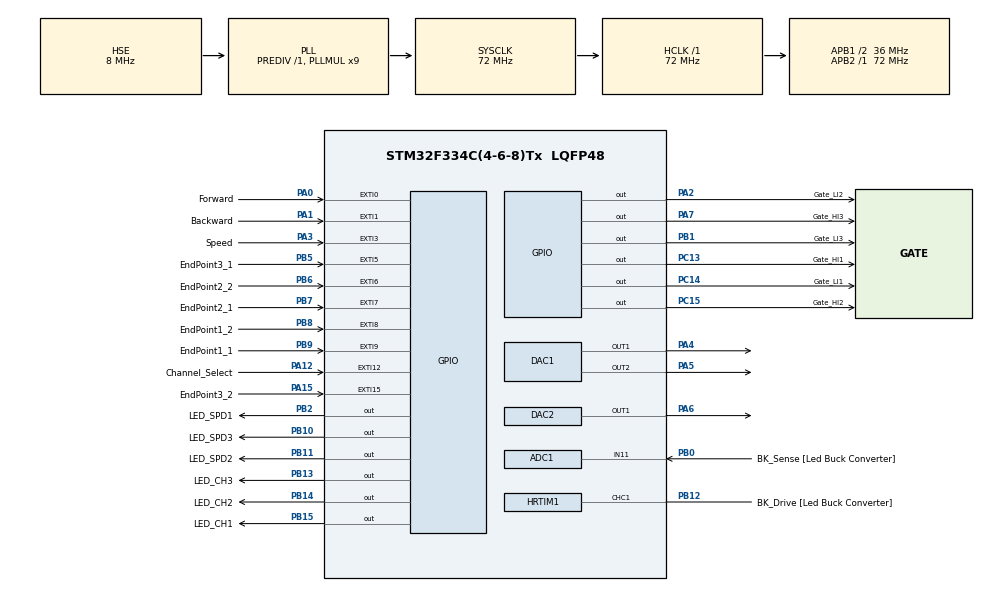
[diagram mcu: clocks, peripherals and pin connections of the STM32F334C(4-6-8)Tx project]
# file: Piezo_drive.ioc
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ADC1.Channel-0\#ChannelRegularConversion=ADC_CHANNEL_11
ADC1.SubFamily=STM32F334x8
ADC1.master=1
DAC1.DAC_Trigger=DAC_TRIGGER_T6_TRGO
DAC1.DAC_Trigger2=DAC_TRIGGER_T6_TRGO
DAC2.DAC_Trigger=DAC_TRIGGER_T6_TRGO
HRTIM1.DMARequests_Semaphore-Output_TC1=ATLEASTONEDMAREQ
HRTIM1.Output1-Output_TC1=HRTIM_OUTPUT_TC1
HRTIM1.TimerIdx-Output_TC1=HRTIM_TIMERINDEX_TIMER_C
Mcu.Family=STM32F3
Mcu.Name=STM32F334C(4-6-8)Tx
Mcu.Package=LQFP48
NVIC.EXTI0_IRQn=true\:0\:0\:true\:false\:true\:true\:true\:true
NVIC.EXTI15_10_IRQn=true\:0\:0\:false\:false\:true\:true\:true\:true
NVIC.EXTI1_IRQn=true\:0\:0\:false\:false\:true\:true\:true\:true
NVIC.EXTI3_IRQn=true\:0\:0\:false\:false\:true\:true\:true\:true
NVIC.EXTI9_5_IRQn=true\:0\:0\:false\:false\:true\:true\:true\:true
NVIC.PriorityGroup=NVIC_PRIORITYGROUP_0
NVIC.TIM6_DAC1_IRQn=true\:0\:0\:false\:false\:true\:true\:true\:true
PA0.GPIO_Label=Forward
PA0.GPIO_ModeDefaultEXTI=GPIO_MODE_IT_RISING_FALLING
PA0.GPIO_PuPd=GPIO_NOPULL
PA0.Signal=GPXTI0
PA1.GPIO_Label=Backward
PA1.GPIO_ModeDefaultEXTI=GPIO_MODE_IT_RISING_FALLING
PA1.Signal=GPXTI1
PA10.GPIO_Label=N2_Drive [Buck/Boost Converter]
PA10.GPIO_ModeDefaultPP=GPIO_MODE_AF_PP
PA10.GPIO_PuPd=GPIO_NOPULL
PA10.GPIO_Speed=GPIO_SPEED_FREQ_LOW
PA10.Signal=HRTIM1_CHB1
PA11.GPIO_Label=P2_Drive [Buck/Boost Converter]
PA11.GPIO_ModeDefaultPP=GPIO_MODE_AF_PP
PA11.GPIO_PuPd=GPIO_NOPULL
PA11.GPIO_Speed=GPIO_SPEED_FREQ_LOW
PA11.Signal=HRTIM1_CHB2
PA12.GPIO_Label=Channel_Select
PA12.Signal=GPXTI12
PA13.GPIO_Label=SWDIO
PA13.Mode=Serial_Wire
PA13.Signal=SYS_JTMS-SWDIO
PA14.GPIO_Label=SWCLK
PA14.Mode=Serial_Wire
PA14.Signal=SYS_JTCK-SWCLK
PA15.GPIO_Label=EndPoint3_2
PA15.Signal=GPXTI15
PA2.GPIO_Label=Gate_LI2
PA2.Signal=GPIO_Output
PA3.GPIO_Label=Speed
PA3.Signal=GPXTI3
PA4.Signal=COMP_DAC11_group
PA5.Signal=COMP_DAC12_group
PA6.Signal=COMP_DAC21_group
PA7.GPIO_Label=Gate_HI3
PA7.Signal=GPIO_Output
PA8.GPIO_Label=P1_Drive [Buck/Boost Converter]
PA8.GPIO_ModeDefaultPP=GPIO_MODE_AF_PP
PA8.GPIO_PuPd=GPIO_NOPULL
PA8.GPIO_Speed=GPIO_SPEED_FREQ_LOW
PA8.Signal=HRTIM1_CHA1
PA9.GPIO_Label=N1_Drive [Buck/Boost Converter]
PA9.GPIO_ModeDefaultPP=GPIO_MODE_AF_PP
PA9.GPIO_PuPd=GPIO_NOPULL
PA9.GPIO_Speed=GPIO_SPEED_FREQ_LOW
PA9.Signal=HRTIM1_CHA2
PB0.GPIO_Label=BK_Sense [Led Buck Converter]
PB0.GPIO_Mode=GPIO_MODE_ANALOG
PB0.GPIO_PuPd=GPIO_NOPULL
PB0.Mode=IN11-Single-Ended
PB0.Signal=ADC1_IN11
PB1.GPIO_Label=Gate_LI3
PB1.Signal=GPIO_Output
PB10.GPIO_Label=LED_SPD3
PB10.Signal=GPIO_Output
PB11.GPIO_Label=LED_SPD2
PB11.Signal=GPIO_Output
PB12.GPIO_Label=BK_Drive [Led Buck Converter]
PB12.GPIO_ModeDefaultPP=GPIO_MODE_AF_PP
PB12.GPIO_PuPd=GPIO_NOPULL
PB12.GPIO_Speed=GPIO_SPEED_FREQ_LOW
PB12.Mode=Output_TC1
PB12.Signal=HRTIM1_CHC1
PB13.GPIO_Label=LED_CH3
PB13.Signal=GPIO_Output
PB14.GPIO_Label=LED_CH2
PB14.Signal=GPIO_Output
PB15.GPIO_Label=LED_CH1
PB15.Signal=GPIO_Output
PB2.GPIO_Label=LED_SPD1
PB2.Signal=GPIO_Output
PB5.GPIO_Label=EndPoint3_1
PB5.Signal=GPXTI5
PB6.GPIO_Label=EndPoint2_2
PB6.Signal=GPXTI6
PB7.GPIO_Label=EndPoint2_1
PB7.Signal=GPXTI7
PB8.GPIO_Label=EndPoint1_2
PB8.Signal=GPXTI8
PB9.GPIO_Label=EndPoint1_1
PB9.Signal=GPXTI9
PC13.GPIO_Label=Gate_HI1
PC13.Signal=GPIO_Output
PC14\ /\ OSC32_IN.GPIO_Label=Gate_LI1
PC14\ /\ OSC32_IN.Signal=GPIO_Output
PC15\ /\ OSC32_OUT.GPIO_Label=Gate_HI2
PC15\ /\ OSC32_OUT.Signal=GPIO_Output
PF0\ /\ OSC_IN.GPIO_Label=PF0-OSC_IN
PF0\ /\ OSC_IN.Mode=HSE-External-Clock-Source
PF0\ /\ OSC_IN.Signal=RCC_OSC_IN
PF1\ /\ OSC_OUT.GPIO_Label=PF1_OSC_OUT
PF1\ /\ OSC_OUT.Signal=RCC_OSC_OUT
ProjectManager.HeapSize=0x200
ProjectManager.StackSize=0x400
ProjectManager.TargetToolchain=STM32CubeIDE
RCC.AHBFreq_Value=72000000
RCC.APB1CLKDivider=RCC_HCLK_DIV2
RCC.APB1Freq_Value=36000000
RCC.APB1TimFreq_Value=72000000
RCC.APB2Freq_Value=72000000
RCC.APB2TimFreq_Value=72000000
RCC.CortexFreq_Value=72000000
RCC.HCLKFreq_Value=72000000
RCC.HSE_VALUE=8000000
RCC.HSI_VALUE=8000000
RCC.LSE_VALUE=32768
RCC.PLLMUL=RCC_PLL_MUL9
RCC.PLLSourceVirtual=RCC_PLLSOURCE_HSE
RCC.SYSCLKFreq_VALUE=72000000
RCC.SYSCLKSourceVirtual=RCC_SYSCLKSOURCE_PLLCLK
SH.COMP_DAC11_group.0=DAC1_OUT1,DAC_OUT1
SH.COMP_DAC12_group.0=DAC1_OUT2,DAC_OUT2
SH.COMP_DAC21_group.0=DAC2_OUT1,Switch_Enable_OUT1
TIM6.Period=16-1
TIM6.Prescaler=32-1
TIM6.TIM_MasterOutputTrigger=TIM_TRGO_UPDATE
VP_TIM6_VS_ClockSourceINT.Mode=Enable_Timer
board=STM32F3348-DISCO

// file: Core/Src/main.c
/* USER CODE BEGIN Header */
/**
  ******************************************************************************
  * @file           : main.c
  * @brief          : Main program body
  ******************************************************************************
  * @attention
  *
  * Copyright (c) 2024 STMicroelectronics.
  * All rights reserved.
  *
  * This software is licensed under terms that can be found in the LICENSE file
  * in the root directory of this software component.
  * If no LICENSE file comes with this software, it is provided AS-IS.
  *
  ******************************************************************************
  */
/* USER CODE END Header */
#include "main.h"

/* USER CODE BEGIN Includes */
#include "stdbool.h"
/* USER CODE END Includes */

/* USER CODE BEGIN PD */
#define Pi 3.1415926
#define lutLen 2048			//Length of the full period
/* USER CODE END PD */

ADC_HandleTypeDef hadc1;

DAC_HandleTypeDef hdac1;
DAC_HandleTypeDef hdac2;

HRTIM_HandleTypeDef hhrtim1;

TIM_HandleTypeDef htim6;

/* USER CODE BEGIN PV */
uint8_t spd = 30;
uint8_t channel = 1;
bool gateOn = false;
bool buttonPress = false;
bool buttonRelease = false;
bool backwards = false;
bool pulse = false;
bool endPoint = false;
bool bootCharging = false;
uint16_t phaseAccumulator = 0;
uint8_t phaseIncrement;
uint8_t pulseLen;
uint16_t pulseAccumulator = 0;
float amplitude;
float offset;
uint16_t phaseShift;
const uint16_t *Lut;
uint16_t periodLen;
uint32_t stepNumber;
uint32_t stepCounter = 0;

//Two full sine periods
const uint16_t sinLut[2*lutLen] = {
32767,32868,32968,33069,33169,33270,33370,33471,
33571,33672,33772,33873,33973,34074,34174,34274,
34375,34475,34576,34676,34776,34877,34977,35077,
35177,35278,35378,35478,35578,35678,35779,35879,
35979,36079,36179,36279,36379,36479,36578,36678,
36778,36878,36977,37077,37177,37276,37376,37475,
37575,37674,37774,37873,37972,38072,38171,38270,
38369,38468,38567,38666,38765,38863,38962,39061,
39160,39258,39357,39455,39553,39652,39750,39848,
39946,40044,40142,40240,40338,40436,40534,40631,
40729,40826,40924,41021,41118,41215,41312,41409,
41506,41603,41700,41797,41893,41990,42086,42183,
42279,42375,42471,42567,42663,42759,42854,42950,
43045,43141,43236,43331,43426,43521,43616,43711,
43806,43900,43995,44089,44184,44278,44372,44466,
44560,44653,44747,44841,44934,45027,45120,45213,
45306,45399,45492,45584,45677,45769,45861,45954,
46046,46137,46229,46321,46412,46503,46595,46686,
46777,46868,46958,47049,47139,47229,47320,47410,
47499,47589,47679,47768,47857,47947,48036,48125,
48213,48302,48390,48479,48567,48655,48743,48830,
48918,49005,49092,49180,49266,49353,49440,49526,
49613,49699,49785,49871,49956,50042,50127,50212,
50297,50382,50467,50551,50636,50720,50804,50888,
50971,51055,51138,51221,51304,51387,51470,51552,
51635,51717,51799,51880,51962,52043,52124,52205,
52286,52367,52447,52528,52608,52688,52767,52847,
52926,53005,53084,53163,53242,53320,53398,53476,
53554,53632,53709,53786,53863,53940,54017,54093,
54170,54246,54321,54397,54472,54548,54623,54697,
54772,54846,54921,54994,55068,55142,55215,55288,
55361,55434,55506,55579,55651,55723,55794,55866,
55937,56008,56078,56149,56219,56289,56359,56429,
56498,56568,56637,56705,56774,56842,56910,56978,
57046,57113,57180,57247,57314,57380,57447,57513,
57578,57644,57709,57774,57839,57904,57968,58032,
58096,58160,58223,58286,58349,58412,58475,58537,
58599,58660,58722,58783,58844,58905,58965,59026,
59086,59145,59205,59264,59323,59382,59441,59499,
59557,59615,59672,59729,59786,59843,59900,59956,
60012,60067,60123,60178,60233,60288,60342,60396,
60450,60504,60557,60610,60663,60716,60768,60820,
60872,60924,60975,61026,61077,61127,61178,61227,
61277,61327,61376,61425,61473,61522,61570,61617,
61665,61712,61759,61806,61852,61898,61944,61990,
62035,62080,62125,62170,62214,62258,62301,62345,
62388,62431,62473,62516,62558,62599,62641,62682,
62723,62764,62804,62844,62884,62923,62962,63001,
63040,63078,63116,63154,63191,63229,63265,63302,
63338,63374,63410,63446,63481,63516,63550,63585,
63619,63652,63686,63719,63752,63784,63817,63849,
63880,63912,63943,63973,64004,64034,64064,64094,
64123,64152,64181,64209,64237,64265,64293,64320,
64347,64374,64400,64426,64452,64477,64503,64527,
64552,64576,64600,64624,64647,64670,64693,64716,
64738,64760,64781,64803,64824,64844,64865,64885,
64904,64924,64943,64962,64980,64999,65017,65034,
65052,65069,65085,65102,65118,65134,65149,65164,
65179,65194,65208,65222,65236,65249,65262,65275,
65288,65300,65312,65323,65334,65345,65356,65366,
65376,65386,65395,65404,65413,65422,65430,65438,
65445,65452,65459,65466,65472,65478,65484,65489,
65495,65499,65504,65508,65512,65515,65519,65522,
65524,65526,65528,65530,65532,65533,65533,65534,
65534,65534,65533,65533,65532,65530,65528,65526,
65524,65522,65519,65515,65512,65508,65504,65499,
65495,65489,65484,65478,65472,65466,65459,65452,
65445,65438,65430,65422,65413,65404,65395,65386,
65376,65366,65356,65345,65334,65323,65312,65300,
65288,65275,65262,65249,65236,65222,65208,65194,
65179,65164,65149,65134,65118,65102,65085,65069,
65052,65034,65017,64999,64980,64962,64943,64924,
64904,64885,64865,64844,64824,64803,64781,64760,
64738,64716,64693,64670,64647,64624,64600,64576,
64552,64527,64503,64477,64452,64426,64400,64374,
64347,64320,64293,64265,64237,64209,64181,64152,
64123,64094,64064,64034,64004,63973,63943,63912,
63880,63849,63817,63784,63752,63719,63686,63652,
63619,63585,63550,63516,63481,63446,63410,63374,
63338,63302,63265,63229,63191,63154,63116,63078,
63040,63001,62962,62923,62884,62844,62804,62764,
62723,62682,62641,62599,62558,62516,62473,62431,
62388,62345,62301,62258,62214,62170,62125,62080,
62035,61990,61944,61898,61852,61806,61759,61712,
61665,61617,61570,61522,61473,61425,61376,61327,
61277,61227,61178,61127,61077,61026,60975,60924,
60872,60820,60768,60716,60663,60610,60557,60504,
60450,60396,60342,60288,60233,60178,60123,60067,
60012,59956,59900,59843,59786,59729,59672,59615,
59557,59499,59441,59382,59323,59264,59205,59145,
59086,59026,58965,58905,58844,58783,58722,58660,
58599,58537,58475,58412,58349,58286,58223,58160,
58096,58032,57968,57904,57839,57774,57709,57644,
57578,57513,57447,57380,57314,57247,57180,57113,
57046,56978,56910,56842,56774,56705,56637,56568,
56498,56429,56359,56289,56219,56149,56078,56008,
55937,55866,55794,55723,55651,55579,55506,55434,
55361,55288,55215,55142,55068,54994,54921,54846,
54772,54697,54623,54548,54472,54397,54321,54246,
54170,54093,54017,53940,53863,53786,53709,53632,
53554,53476,53398,53320,53242,53163,53084,53005,
52926,52847,52767,52688,52608,52528,52447,52367,
52286,52205,52124,52043,51962,51880,51799,51717,
51635,51552,51470,51387,51304,51221,51138,51055,
50971,50888,50804,50720,50636,50551,50467,50382,
50297,50212,50127,50042,49956,49871,49785,49699,
49613,49526,49440,49353,49266,49180,49092,49005,
48918,48830,48743,48655,48567,48479,48390,48302,
48213,48125,48036,47947,47857,47768,47679,47589,
47499,47410,47320,47229,47139,47049,46958,46868,
46777,46686,46595,46503,46412,46321,46229,46137,
46046,45954,45861,45769,45677,45584,45492,45399,
45306,45213,45120,45027,44934,44841,44747,44653,
44560,44466,44372,44278,44184,44089,43995,43900,
43806,43711,43616,43521,43426,43331,43236,43141,
43045,42950,42854,42759,42663,42567,42471,42375,
42279,42183,42086,41990,41893,41797,41700,41603,
41506,41409,41312,41215,41118,41021,40924,40826,
40729,40631,40534,40436,40338,40240,40142,40044,
39946,39848,39750,39652,39553,39455,39357,39258,
39160,39061,38962,38863,38765,38666,38567,38468,
38369,38270,38171,38072,37972,37873,37774,37674,
37575,37475,37376,37276,37177,37077,36977,36878,
36778,36678,36578,36479,36379,36279,36179,36079,
35979,35879,35779,35678,35578,35478,35378,35278,
35177,35077,34977,34877,34776,34676,34576,34475,
34375,34274,34174,34074,33973,33873,33772,33672,
33571,33471,33370,33270,33169,33069,32968,32868,
32767,32666,32566,32465,32365,32264,32164,32063,
31963,31862,31762,31661,31561,31460,31360,31260,
31159,31059,30958,30858,30758,30657,30557,30457,
30357,30256,30156,30056,29956,29856,29755,29655,
29555,29455,29355,29255,29155,29055,28956,28856,
28756,28656,28557,28457,28357,28258,28158,28059,
27959,27860,27760,27661,27562,27462,27363,27264,
27165,27066,26967,26868,26769,26671,26572,26473,
26374,26276,26177,26079,25981,25882,25784,25686,
25588,25490,25392,25294,25196,25098,25000,24903,
24805,24708,24610,24513,24416,24319,24222,24125,
24028,23931,23834,23737,23641,23544,23448,23351,
23255,23159,23063,22967,22871,22775,22680,22584,
22489,22393,22298,22203,22108,22013,21918,21823,
21728,21634,21539,21445,21350,21256,21162,21068,
20974,20881,20787,20693,20600,20507,20414,20321,
20228,20135,20042,19950,19857,19765,19673,19580,
19488,19397,19305,19213,19122,19031,18939,18848,
18757,18666,18576,18485,18395,18305,18214,18124,
18035,17945,17855,17766,17677,17587,17498,17409,
17321,17232,17144,17055,16967,16879,16791,16704,
16616,16529,16442,16354,16268,16181,16094,16008,
15921,15835,15749,15663,15578,15492,15407,15322,
15237,15152,15067,14983,14898,14814,14730,14646,
14563,14479,14396,14313,14230,14147,14064,13982,
13899,13817,13735,13654,13572,13491,13410,13329,
13248,13167,13087,13006,12926,12846,12767,12687,
12608,12529,12450,12371,12292,12214,12136,12058,
11980,11902,11825,11748,11671,11594,11517,11441,
11364,11288,11213,11137,11062,10986,10911,10837,
10762,10688,10613,10540,10466,10392,10319,10246,
10173,10100,10028, 9955, 9883, 9811, 9740, 9668,
 9597, 9526, 9456, 9385, 9315, 9245, 9175, 9105,
 9036, 8966, 8897, 8829, 8760, 8692, 8624, 8556,
 8488, 8421, 8354, 8287, 8220, 8154, 8087, 8021,
 7956, 7890, 7825, 7760, 7695, 7630, 7566, 7502,
 7438, 7374, 7311, 7248, 7185, 7122, 7059, 6997,
 6935, 6874, 6812, 6751, 6690, 6629, 6569, 6508,
 6448, 6389, 6329, 6270, 6211, 6152, 6093, 6035,
 5977, 5919, 5862, 5805, 5748, 5691, 5634, 5578,
 5522, 5467, 5411, 5356, 5301, 5246, 5192, 5138,
 5084, 5030, 4977, 4924, 4871, 4818, 4766, 4714,
 4662, 4610, 4559, 4508, 4457, 4407, 4356, 4307,
 4257, 4207, 4158, 4109, 4061, 4012, 3964, 3917,
 3869, 3822, 3775, 3728, 3682, 3636, 3590, 3544,
 3499, 3454, 3409, 3364, 3320, 3276, 3233, 3189,
 3146, 3103, 3061, 3018, 2976, 2935, 2893, 2852,
 2811, 2770, 2730, 2690, 2650, 2611, 2572, 2533,
 2494, 2456, 2418, 2380, 2343, 2305, 2269, 2232,
 2196, 2160, 2124, 2088, 2053, 2018, 1984, 1949,
 1915, 1882, 1848, 1815, 1782, 1750, 1717, 1685,
 1654, 1622, 1591, 1561, 1530, 1500, 1470, 1440,
 1411, 1382, 1353, 1325, 1297, 1269, 1241, 1214,
 1187, 1160, 1134, 1108, 1082, 1057, 1031, 1007,
  982,  958,  934,  910,  887,  864,  841,  818,
  796,  774,  753,  731,  710,  690,  669,  649,
  630,  610,  591,  572,  554,  535,  517,  500,
  482,  465,  449,  432,  416,  400,  385,  370,
  355,  340,  326,  312,  298,  285,  272,  259,
  246,  234,  222,  211,  200,  189,  178,  168,
  158,  148,  139,  130,  121,  112,  104,   96,
   89,   82,   75,   68,   62,   56,   50,   45,
   39,   35,   30,   26,   22,   19,   15,   12,
   10,    8,    6,    4,    2,    1,    1,    0,
    0,    0,    1,    1,    2,    4,    6,    8,
   10,   12,   15,   19,   22,   26,   30,   35,
   39,   45,   50,   56,   62,   68,   75,   82,
   89,   96,  104,  112,  121,  130,  139,  148,
  158,  168,  178,  189,  200,  211,  222,  234,
  246,  259,  272,  285,  298,  312,  326,  340,
  355,  370,  385,  400,  416,  432,  449,  465,
  482,  500,  517,  535,  554,  572,  591,  610,
  630,  649,  669,  690,  710,  731,  753,  774,
  796,  818,  841,  864,  887,  910,  934,  958,
  982, 1007, 1031, 1057, 1082, 1108, 1134, 1160,
 1187, 1214, 1241, 1269, 1297, 1325, 1353, 1382,
 1411, 1440, 1470, 1500, 1530, 1561, 1591, 1622,
 1654, 1685, 1717, 1750, 1782, 1815, 1848, 1882,
 1915, 1949, 1984, 2018, 2053, 2088, 2124, 2160,
 2196, 2232, 2269, 2305, 2343, 2380, 2418, 2456,
 2494, 2533, 2572, 2611, 2650, 2690, 2730, 2770,
 2811, 2852, 2893, 2935, 2976, 3018, 3061, 3103,
 3146, 3189, 3233, 3276, 3320, 3364, 3409, 3454,
 3499, 3544, 3590, 3636, 3682, 3728, 3775, 3822,
 3869, 3917, 3964, 4012, 4061, 4109, 4158, 4207,
 4257, 4307, 4356, 4407, 4457, 4508, 4559, 4610,
 4662, 4714, 4766, 4818, 4871, 4924, 4977, 5030,
 5084, 5138, 5192, 5246, 5301, 5356, 5411, 5467,
 5522, 5578, 5634, 5691, 5748, 5805, 5862, 5919,
 5977, 6035, 6093, 6152, 6211, 6270, 6329, 6389,
 6448, 6508, 6569, 6629, 6690, 6751, 6812, 6874,
 6935, 6997, 7059, 7122, 7185, 7248, 7311, 7374,
 7438, 7502, 7566, 7630, 7695, 7760, 7825, 7890,
 7956, 8021, 8087, 8154, 8220, 8287, 8354, 8421,
 8488, 8556, 8624, 8692, 8760, 8829, 8897, 8966,
 9036, 9105, 9175, 9245, 9315, 9385, 9456, 9526,
 9597, 9668, 9740, 9811, 9883, 9955,10028,10100,
10173,10246,10319,10392,10466,10540,10613,10688,
10762,10837,10911,10986,11062,11137,11213,11288,
11364,11441,11517,11594,11671,11748,11825,11902,
11980,12058,12136,12214,12292,12371,12450,12529,
12608,12687,12767,12846,12926,13006,13087,13167,
13248,13329,13410,13491,13572,13654,13735,13817,
13899,13982,14064,14147,14230,14313,14396,14479,
14563,14646,14730,14814,14898,14983,15067,15152,
15237,15322,15407,15492,15578,15663,15749,15835,
15921,16008,16094,16181,16268,16354,16442,16529,
16616,16704,16791,16879,16967,17055,17144,17232,
17321,17409,17498,17587,17677,17766,17855,17945,
18035,18124,18214,18305,18395,18485,18576,18666,
18757,18848,18939,19031,19122,19213,19305,19397,
19488,19580,19673,19765,19857,19950,20042,20135,
20228,20321,20414,20507,20600,20693,20787,20881,
20974,21068,21162,21256,21350,21445,21539,21634,
21728,21823,21918,22013,22108,22203,22298,22393,
22489,22584,22680,22775,22871,22967,23063,23159,
23255,23351,23448,23544,23641,23737,23834,23931,
24028,24125,24222,24319,24416,24513,24610,24708,
24805,24903,25000,25098,25196,25294,25392,25490,
25588,25686,25784,25882,25981,26079,26177,26276,
26374,26473,26572,26671,26769,26868,26967,27066,
27165,27264,27363,27462,27562,27661,27760,27860,
27959,28059,28158,28258,28357,28457,28557,28656,
28756,28856,28956,29055,29155,29255,29355,29455,
29555,29655,29755,29856,29956,30056,30156,30256,
30357,30457,30557,30657,30758,30858,30958,31059,
31159,31260,31360,31460,31561,31661,31762,31862,
31963,32063,32164,32264,32365,32465,32566,32666,
32767,32868,32968,33069,33169,33270,33370,33471,
33571,33672,33772,33873,33973,34074,34174,34274,
34375,34475,34576,34676,34776,34877,34977,35077,
35177,35278,35378,35478,35578,35678,35779,35879,
35979,36079,36179,36279,36379,36479,36578,36678,
36778,36878,36977,37077,37177,37276,37376,37475,
37575,37674,37774,37873,37972,38072,38171,38270,
38369,38468,38567,38666,38765,38863,38962,39061,
39160,39258,39357,39455,39553,39652,39750,39848,
39946,40044,40142,40240,40338,40436,40534,40631,
40729,40826,40924,41021,41118,41215,41312,41409,
41506,41603,41700,41797,41893,41990,42086,42183,
42279,42375,42471,42567,42663,42759,42854,42950,
43045,43141,43236,43331,43426,43521,43616,43711,
43806,43900,43995,44089,44184,44278,44372,44466,
44560,44653,44747,44841,44934,45027,45120,45213,
45306,45399,45492,45584,45677,45769,45861,45954,
46046,46137,46229,46321,46412,46503,46595,46686,
46777,46868,46958,47049,47139,47229,47320,47410,
47499,47589,47679,47768,47857,47947,48036,48125,
48213,48302,48390,48479,48567,48655,48743,48830,
48918,49005,49092,49180,49266,49353,49440,49526,
49613,49699,49785,49871,49956,50042,50127,50212,
50297,50382,50467,50551,50636,50720,50804,50888,
50971,51055,51138,51221,51304,51387,51470,51552,
51635,51717,51799,51880,51962,52043,52124,52205,
52286,52367,52447,52528,52608,52688,52767,52847,
52926,53005,53084,53163,53242,53320,53398,53476,
53554,53632,53709,53786,53863,53940,54017,54093,
54170,54246,54321,54397,54472,54548,54623,54697,
54772,54846,54921,54994,55068,55142,55215,55288,
55361,55434,55506,55579,55651,55723,55794,55866,
55937,56008,56078,56149,56219,56289,56359,56429,
56498,56568,56637,56705,56774,56842,56910,56978,
57046,57113,57180,57247,57314,57380,57447,57513,
57578,57644,57709,57774,57839,57904,57968,58032,
58096,58160,58223,58286,58349,58412,58475,58537,
58599,58660,58722,58783,58844,58905,58965,59026,
59086,59145,59205,59264,59323,59382,59441,59499,
59557,59615,59672,59729,59786,59843,59900,59956,
60012,60067,60123,60178,60233,60288,60342,60396,
60450,60504,60557,60610,60663,60716,60768,60820,
60872,60924,60975,61026,61077,61127,61178,61227,
61277,61327,61376,61425,61473,61522,61570,61617,
61665,61712,61759,61806,61852,61898,61944,61990,
62035,62080,62125,62170,62214,62258,62301,62345,
62388,62431,62473,62516,62558,62599,62641,62682,
62723,62764,62804,62844,62884,62923,62962,63001,
63040,63078,63116,63154,63191,63229,63265,63302,
63338,63374,63410,63446,63481,63516,63550,63585,
63619,63652,63686,63719,63752,63784,63817,63849,
63880,63912,63943,63973,64004,64034,64064,64094,
64123,64152,64181,64209,64237,64265,64293,64320,
64347,64374,64400,64426,64452,64477,64503,64527,
64552,64576,64600,64624,64647,64670,64693,64716,
64738,64760,64781,64803,64824,64844,64865,64885,
64904,64924,64943,64962,64980,64999,65017,65034,
65052,65069,65085,65102,65118,65134,65149,65164,
65179,65194,65208,65222,65236,65249,65262,65275,
65288,65300,65312,65323,65334,65345,65356,65366,
65376,65386,65395,65404,65413,65422,65430,65438,
65445,65452,65459,65466,65472,65478,65484,65489,
65495,65499,65504,65508,65512,65515,65519,65522,
65524,65526,65528,65530,65532,65533,65533,65534,
65534,65534,65533,65533,65532,65530,65528,65526,
65524,65522,65519,65515,65512,65508,65504,65499,
65495,65489,65484,65478,65472,65466,65459,65452,
65445,65438,65430,65422,65413,65404,65395,65386,
65376,65366,65356,65345,65334,65323,65312,65300,
65288,65275,65262,65249,65236,65222,65208,65194,
65179,65164,65149,65134,65118,65102,65085,65069,
65052,65034,65017,64999,64980,64962,64943,64924,
64904,64885,64865,64844,64824,64803,64781,64760,
64738,64716,64693,64670,64647,64624,64600,64576,
64552,64527,64503,64477,64452,64426,64400,64374,
64347,64320,64293,64265,64237,64209,64181,64152,
64123,64094,64064,64034,64004,63973,63943,63912,
63880,63849,63817,63784,63752,63719,63686,63652,
63619,63585,63550,63516,63481,63446,63410,63374,
63338,63302,63265,63229,63191,63154,63116,63078,
63040,63001,62962,62923,62884,62844,62804,62764,
62723,62682,62641,62599,62558,62516,62473,62431,
62388,62345,62301,62258,62214,62170,62125,62080,
62035,61990,61944,61898,61852,61806,61759,61712,
61665,61617,61570,61522,61473,61425,61376,61327,
61277,61227,61178,61127,61077,61026,60975,60924,
60872,60820,60768,60716,60663,60610,60557,60504,
60450,60396,60342,60288,60233,60178,60123,60067,
60012,59956,59900,59843,59786,59729,59672,59615,
59557,59499,59441,59382,59323,59264,59205,59145,
59086,59026,58965,58905,58844,58783,58722,58660,
58599,58537,58475,58412,58349,58286,58223,58160,
58096,58032,57968,57904,57839,57774,57709,57644,
57578,57513,57447,57380,57314,57247,57180,57113,
57046,56978,56910,56842,56774,56705,56637,56568,
56498,56429,56359,56289,56219,56149,56078,56008,
55937,55866,55794,55723,55651,55579,55506,55434,
55361,55288,55215,55142,55068,54994,54921,54846,
54772,54697,54623,54548,54472,54397,54321,54246,
54170,54093,54017,53940,53863,53786,53709,53632,
53554,53476,53398,53320,53242,53163,53084,53005,
52926,52847,52767,52688,52608,52528,52447,52367,
52286,52205,52124,52043,51962,51880,51799,51717,
51635,51552,51470,51387,51304,51221,51138,51055,
50971,50888,50804,50720,50636,50551,50467,50382,
50297,50212,50127,50042,49956,49871,49785,49699,
49613,49526,49440,49353,49266,49180,49092,49005,
48918,48830,48743,48655,48567,48479,48390,48302,
48213,48125,48036,47947,47857,47768,47679,47589,
47499,47410,47320,47229,47139,47049,46958,46868,
46777,46686,46595,46503,46412,46321,46229,46137,
46046,45954,45861,45769,45677,45584,45492,45399,
45306,45213,45120,45027,44934,44841,44747,44653,
44560,44466,44372,44278,44184,44089,43995,43900,
43806,43711,43616,43521,43426,43331,43236,43141,
43045,42950,42854,42759,42663,42567,42471,42375,
42279,42183,42086,41990,41893,41797,41700,41603,
41506,41409,41312,41215,41118,41021,40924,40826,
40729,40631,40534,40436,40338,40240,40142,40044,
39946,39848,39750,39652,39553,39455,39357,39258,
39160,39061,38962,38863,38765,38666,38567,38468,
38369,38270,38171,38072,37972,37873,37774,37674,
37575,37475,37376,37276,37177,37077,36977,36878,
36778,36678,36578,36479,36379,36279,36179,36079,
35979,35879,35779,35678,35578,35478,35378,35278,
35177,35077,34977,34877,34776,34676,34576,34475,
34375,34274,34174,34074,33973,33873,33772,33672,
33571,33471,33370,33270,33169,33069,32968,32868,
32767,32666,32566,32465,32365,32264,32164,32063,
31963,31862,31762,31661,31561,31460,31360,31260,
31159,31059,30958,30858,30758,30657,30557,30457,
30357,30256,30156,30056,29956,29856,29755,29655,
29555,29455,29355,29255,29155,29055,28956,28856,
28756,28656,28557,28457,28357,28258,28158,28059,
27959,27860,27760,27661,27562,27462,27363,27264,
27165,27066,26967,26868,26769,26671,26572,26473,
26374,26276,26177,26079,25981,25882,25784,25686,
25588,25490,25392,25294,25196,25098,25000,24903,
24805,24708,24610,24513,24416,24319,24222,24125,
24028,23931,23834,23737,23641,23544,23448,23351,
23255,23159,23063,22967,22871,22775,22680,22584,
22489,22393,22298,22203,22108,22013,21918,21823,
21728,21634,21539,21445,21350,21256,21162,21068,
20974,20881,20787,20693,20600,20507,20414,20321,
20228,20135,20042,19950,19857,19765,19673,19580,
19488,19397,19305,19213,19122,19031,18939,18848,
18757,18666,18576,18485,18395,18305,18214,18124,
18035,17945,17855,17766,17677,17587,17498,17409,
17321,17232,17144,17055,16967,16879,16791,16704,
16616,16529,16442,16354,16268,16181,16094,16008,
15921,15835,15749,15663,15578,15492,15407,15322,
15237,15152,15067,14983,14898,14814,14730,14646,
14563,14479,14396,14313,14230,14147,14064,13982,
13899,13817,13735,13654,13572,13491,13410,13329,
13248,13167,13087,13006,12926,12846,12767,12687,
12608,12529,12450,12371,12292,12214,12136,12058,
11980,11902,11825,11748,11671,11594,11517,11441,
11364,11288,11213,11137,11062,10986,10911,10837,
10762,10688,10613,10540,10466,10392,10319,10246,
10173,10100,10028, 9955, 9883, 9811, 9740, 9668,
 9597, 9526, 9456, 9385, 9315, 9245, 9175, 9105,
 9036, 8966, 8897, 8829, 8760, 8692, 8624, 8556,
 8488, 8421, 8354, 8287, 8220, 8154, 8087, 8021,
 7956, 7890, 7825, 7760, 7695, 7630, 7566, 7502,
 7438, 7374, 7311, 7248, 7185, 7122, 7059, 6997,
 6935, 6874, 6812, 6751, 6690, 6629, 6569, 6508,
 6448, 6389, 6329, 6270, 6211, 6152, 6093, 6035,
 5977, 5919, 5862, 5805, 5748, 5691, 5634, 5578,
 5522, 5467, 5411, 5356, 5301, 5246, 5192, 5138,
 5084, 5030, 4977, 4924, 4871, 4818, 4766, 4714,
 4662, 4610, 4559, 4508, 4457, 4407, 4356, 4307,
 4257, 4207, 4158, 4109, 4061, 4012, 3964, 3917,
 3869, 3822, 3775, 3728, 3682, 3636, 3590, 3544,
 3499, 3454, 3409, 3364, 3320, 3276, 3233, 3189,
 3146, 3103, 3061, 3018, 2976, 2935, 2893, 2852,
 2811, 2770, 2730, 2690, 2650, 2611, 2572, 2533,
 2494, 2456, 2418, 2380, 2343, 2305, 2269, 2232,
 2196, 2160, 2124, 2088, 2053, 2018, 1984, 1949,
 1915, 1882, 1848, 1815, 1782, 1750, 1717, 1685,
 1654, 1622, 1591, 1561, 1530, 1500, 1470, 1440,
 1411, 1382, 1353, 1325, 1297, 1269, 1241, 1214,
 1187, 1160, 1134, 1108, 1082, 1057, 1031, 1007,
  982,  958,  934,  910,  887,  864,  841,  818,
  796,  774,  753,  731,  710,  690,  669,  649,
  630,  610,  591,  572,  554,  535,  517,  500,
  482,  465,  449,  432,  416,  400,  385,  370,
  355,  340,  326,  312,  298,  285,  272,  259,
  246,  234,  222,  211,  200,  189,  178,  168,
  158,  148,  139,  130,  121,  112,  104,   96,
   89,   82,   75,   68,   62,   56,   50,   45,
   39,   35,   30,   26,   22,   19,   15,   12,
   10,    8,    6,    4,    2,    1,    1,    0,
    0,    0,    1,    1,    2,    4,    6,    8,
   10,   12,   15,   19,   22,   26,   30,   35,
   39,   45,   50,   56,   62,   68,   75,   82,
   89,   96,  104,  112,  121,  130,  139,  148,
  158,  168,  178,  189,  200,  211,  222,  234,
  246,  259,  272,  285,  298,  312,  326,  340,
  355,  370,  385,  400,  416,  432,  449,  465,
  482,  500,  517,  535,  554,  572,  591,  610,
  630,  649,  669,  690,  710,  731,  753,  774,
  796,  818,  841,  864,  887,  910,  934,  958,
  982, 1007, 1031, 1057, 1082, 1108, 1134, 1160,
 1187, 1214, 1241, 1269, 1297, 1325, 1353, 1382,
 1411, 1440, 1470, 1500, 1530, 1561, 1591, 1622,
 1654, 1685, 1717, 1750, 1782, 1815, 1848, 1882,
 1915, 1949, 1984, 2018, 2053, 2088, 2124, 2160,
 2196, 2232, 2269, 2305, 2343, 2380, 2418, 2456,
 2494, 2533, 2572, 2611, 2650, 2690, 2730, 2770,
 2811, 2852, 2893, 2935, 2976, 3018, 3061, 3103,
 3146, 3189, 3233, 3276, 3320, 3364, 3409, 3454,
 3499, 3544, 3590, 3636, 3682, 3728, 3775, 3822,
 3869, 3917, 3964, 4012, 4061, 4109, 4158, 4207,
 4257, 4307, 4356, 4407, 4457, 4508, 4559, 4610,
 4662, 4714, 4766, 4818, 4871, 4924, 4977, 5030,
 5084, 5138, 5192, 5246, 5301, 5356, 5411, 5467,
 5522, 5578, 5634, 5691, 5748, 5805, 5862, 5919,
 5977, 6035, 6093, 6152, 6211, 6270, 6329, 6389,
 6448, 6508, 6569, 6629, 6690, 6751, 6812, 6874,
 6935, 6997, 7059, 7122, 7185, 7248, 7311, 7374,
 7438, 7502, 7566, 7630, 7695, 7760, 7825, 7890,
 7956, 8021, 8087, 8154, 8220, 8287, 8354, 8421,
 8488, 8556, 8624, 8692, 8760, 8829, 8897, 8966,
 9036, 9105, 9175, 9245, 9315, 9385, 9456, 9526,
 9597, 9668, 9740, 9811, 9883, 9955,10028,10100,
10173,10246,10319,10392,10466,10540,10613,10688,
10762,10837,10911,10986,11062,11137,11213,11288,
11364,11441,11517,11594,11671,11748,11825,11902,
11980,12058,12136,12214,12292,12371,12450,12529,
12608,12687,12767,12846,12926,13006,13087,13167,
13248,13329,13410,13491,13572,13654,13735,13817,
13899,13982,14064,14147,14230,14313,14396,14479,
14563,14646,14730,14814,14898,14983,15067,15152,
15237,15322,15407,15492,15578,15663,15749,15835,
15921,16008,16094,16181,16268,16354,16442,16529,
16616,16704,16791,16879,16967,17055,17144,17232,
17321,17409,17498,17587,17677,17766,17855,17945,
18035,18124,18214,18305,18395,18485,18576,18666,
18757,18848,18939,19031,19122,19213,19305,19397,
19488,19580,19673,19765,19857,19950,20042,20135,
20228,20321,20414,20507,20600,20693,20787,20881,
20974,21068,21162,21256,21350,21445,21539,21634,
21728,21823,21918,22013,22108,22203,22298,22393,
22489,22584,22680,22775,22871,22967,23063,23159,
23255,23351,23448,23544,23641,23737,23834,23931,
24028,24125,24222,24319,24416,24513,24610,24708,
24805,24903,25000,25098,25196,25294,25392,25490,
25588,25686,25784,25882,25981,26079,26177,26276,
26374,26473,26572,26671,26769,26868,26967,27066,
27165,27264,27363,27462,27562,27661,27760,27860,
27959,28059,28158,28258,28357,28457,28557,28656,
28756,28856,28956,29055,29155,29255,29355,29455,
29555,29655,29755,29856,29956,30056,30156,30256,
30357,30457,30557,30657,30758,30858,30958,31059,
31159,31260,31360,31460,31561,31661,31762,31862,
31963,32063,32164,32264,32365,32465,32566,32666 };

/** Generated using Dr LUT - Free Lookup Table Generator
 * https://github.com/ppelikan/drlut
 **/
// Formula: 4*abs(t/T-floor(t/T+1/2))-1
const uint16_t sawLut[lutLen] = {
   0,   64,  128,  192,  256,  320,  384,  448,
 512,  576,  640,  704,  768,  832,  896,  960,
1024, 1088, 1152, 1216, 1280, 1344, 1408, 1472,
1536, 1600, 1664, 1728, 1792, 1856, 1920, 1984,
2048, 2112, 2176, 2240, 2304, 2368, 2432, 2496,
2560, 2624, 2688, 2752, 2816, 2880, 2944, 3008,
3072, 3136, 3200, 3264, 3328, 3392, 3456, 3520,
3584, 3648, 3712, 3776, 3840, 3904, 3968, 4032,
4096, 4160, 4224, 4288, 4352, 4416, 4480, 4544,
4608, 4672, 4736, 4800, 4864, 4928, 4992, 5056,
5120, 5184, 5248, 5312, 5376, 5440, 5504, 5568,
5632, 5696, 5760, 5824, 5888, 5952, 6016, 6080,
6144, 6208, 6272, 6336, 6400, 6464, 6528, 6592,
6656, 6720, 6784, 6848, 6912, 6976, 7040, 7104,
7168, 7232, 7296, 7360, 7424, 7488, 7552, 7616,
7680, 7744, 7808, 7872, 7936, 8000, 8064, 8128,
8192, 8256, 8320, 8384, 8448, 8512, 8576, 8640,
8704, 8768, 8832, 8896, 8960, 9024, 9088, 9152,
9216, 9280, 9344, 9408, 9472, 9536, 9600, 9664,
9728, 9792, 9856, 9920, 9984,10048,10112,10176,
10240,10304,10368,10432,10496,10560,10624,10688,
10752,10816,10880,10944,11008,11072,11136,11200,
11264,11328,11392,11456,11520,11584,11648,11712,
11776,11840,11904,11968,12032,12096,12160,12224,
12288,12352,12416,12480,12544,12608,12672,12736,
12800,12864,12928,12992,13056,13120,13184,13248,
13312,13376,13440,13504,13568,13632,13696,13760,
13824,13888,13952,14016,14080,14144,14208,14272,
14336,14400,14464,14528,14592,14656,14720,14784,
14848,14912,14976,15040,15104,15168,15232,15296,
15360,15424,15488,15552,15616,15680,15744,15808,
15872,15936,16000,16064,16128,16192,16256,16320,
16384,16447,16511,16575,16639,16703,16767,16831,
16895,16959,17023,17087,17151,17215,17279,17343,
17407,17471,17535,17599,17663,17727,17791,17855,
17919,17983,18047,18111,18175,18239,18303,18367,
18431,18495,18559,18623,18687,18751,18815,18879,
18943,19007,19071,19135,19199,19263,19327,19391,
19455,19519,19583,19647,19711,19775,19839,19903,
19967,20031,20095,20159,20223,20287,20351,20415,
20479,20543,20607,20671,20735,20799,20863,20927,
20991,21055,21119,21183,21247,21311,21375,21439,
21503,21567,21631,21695,21759,21823,21887,21951,
22015,22079,22143,22207,22271,22335,22399,22463,
22527,22591,22655,22719,22783,22847,22911,22975,
23039,23103,23167,23231,23295,23359,23423,23487,
23551,23615,23679,23743,23807,23871,23935,23999,
24063,24127,24191,24255,24319,24383,24447,24511,
24575,24639,24703,24767,24831,24895,24959,25023,
25087,25151,25215,25279,25343,25407,25471,25535,
25599,25663,25727,25791,25855,25919,25983,26047,
26111,26175,26239,26303,26367,26431,26495,26559,
26623,26687,26751,26815,26879,26943,27007,27071,
27135,27199,27263,27327,27391,27455,27519,27583,
27647,27711,27775,27839,27903,27967,28031,28095,
28159,28223,28287,28351,28415,28479,28543,28607,
28671,28735,28799,28863,28927,28991,29055,29119,
29183,29247,29311,29375,29439,29503,29567,29631,
29695,29759,29823,29887,29951,30015,30079,30143,
30207,30271,30335,30399,30463,30527,30591,30655,
30719,30783,30847,30911,30975,31039,31103,31167,
31231,31295,31359,31423,31487,31551,31615,31679,
31743,31807,31871,31935,31999,32063,32127,32191,
32255,32319,32383,32447,32511,32575,32639,32703,
32767,32831,32895,32959,33023,33087,33151,33215,
33279,33343,33407,33471,33535,33599,33663,33727,
33791,33855,33919,33983,34047,34111,34175,34239,
34303,34367,34431,34495,34559,34623,34687,34751,
34815,34879,34943,35007,35071,35135,35199,35263,
35327,35391,35455,35519,35583,35647,35711,35775,
35839,35903,35967,36031,36095,36159,36223,36287,
36351,36415,36479,36543,36607,36671,36735,36799,
36863,36927,36991,37055,37119,37183,37247,37311,
37375,37439,37503,37567,37631,37695,37759,37823,
37887,37951,38015,38079,38143,38207,38271,38335,
38399,38463,38527,38591,38655,38719,38783,38847,
38911,38975,39039,39103,39167,39231,39295,39359,
39423,39487,39551,39615,39679,39743,39807,39871,
39935,39999,40063,40127,40191,40255,40319,40383,
40447,40511,40575,40639,40703,40767,40831,40895,
40959,41023,41087,41151,41215,41279,41343,41407,
41471,41535,41599,41663,41727,41791,41855,41919,
41983,42047,42111,42175,42239,42303,42367,42431,
42495,42559,42623,42687,42751,42815,42879,42943,
43007,43071,43135,43199,43263,43327,43391,43455,
43519,43583,43647,43711,43775,43839,43903,43967,
44031,44095,44159,44223,44287,44351,44415,44479,
44543,44607,44671,44735,44799,44863,44927,44991,
45055,45119,45183,45247,45311,45375,45439,45503,
45567,45631,45695,45759,45823,45887,45951,46015,
46079,46143,46207,46271,46335,46399,46463,46527,
46591,46655,46719,46783,46847,46911,46975,47039,
47103,47167,47231,47295,47359,47423,47487,47551,
47615,47679,47743,47807,47871,47935,47999,48063,
48127,48191,48255,48319,48383,48447,48511,48575,
48639,48703,48767,48831,48895,48959,49023,49087,
49150,49214,49278,49342,49406,49470,49534,49598,
49662,49726,49790,49854,49918,49982,50046,50110,
50174,50238,50302,50366,50430,50494,50558,50622,
50686,50750,50814,50878,50942,51006,51070,51134,
51198,51262,51326,51390,51454,51518,51582,51646,
51710,51774,51838,51902,51966,52030,52094,52158,
52222,52286,52350,52414,52478,52542,52606,52670,
52734,52798,52862,52926,52990,53054,53118,53182,
53246,53310,53374,53438,53502,53566,53630,53694,
53758,53822,53886,53950,54014,54078,54142,54206,
54270,54334,54398,54462,54526,54590,54654,54718,
54782,54846,54910,54974,55038,55102,55166,55230,
55294,55358,55422,55486,55550,55614,55678,55742,
55806,55870,55934,55998,56062,56126,56190,56254,
56318,56382,56446,56510,56574,56638,56702,56766,
56830,56894,56958,57022,57086,57150,57214,57278,
57342,57406,57470,57534,57598,57662,57726,57790,
57854,57918,57982,58046,58110,58174,58238,58302,
58366,58430,58494,58558,58622,58686,58750,58814,
58878,58942,59006,59070,59134,59198,59262,59326,
59390,59454,59518,59582,59646,59710,59774,59838,
59902,59966,60030,60094,60158,60222,60286,60350,
60414,60478,60542,60606,60670,60734,60798,60862,
60926,60990,61054,61118,61182,61246,61310,61374,
61438,61502,61566,61630,61694,61758,61822,61886,
61950,62014,62078,62142,62206,62270,62334,62398,
62462,62526,62590,62654,62718,62782,62846,62910,
62974,63038,63102,63166,63230,63294,63358,63422,
63486,63550,63614,63678,63742,63806,63870,63934,
63998,64062,64126,64190,64254,64318,64382,64446,
64510,64574,64638,64702,64766,64830,64894,64958,
65022,65086,65150,65214,65278,65342,65406,65470,
65534,65470,65406,65342,65278,65214,65150,65086,
65022,64958,64894,64830,64766,64702,64638,64574,
64510,64446,64382,64318,64254,64190,64126,64062,
63998,63934,63870,63806,63742,63678,63614,63550,
63486,63422,63358,63294,63230,63166,63102,63038,
62974,62910,62846,62782,62718,62654,62590,62526,
62462,62398,62334,62270,62206,62142,62078,62014,
61950,61886,61822,61758,61694,61630,61566,61502,
61438,61374,61310,61246,61182,61118,61054,60990,
60926,60862,60798,60734,60670,60606,60542,60478,
60414,60350,60286,60222,60158,60094,60030,59966,
59902,59838,59774,59710,59646,59582,59518,59454,
59390,59326,59262,59198,59134,59070,59006,58942,
58878,58814,58750,58686,58622,58558,58494,58430,
58366,58302,58238,58174,58110,58046,57982,57918,
57854,57790,57726,57662,57598,57534,57470,57406,
57342,57278,57214,57150,57086,57022,56958,56894,
56830,56766,56702,56638,56574,56510,56446,56382,
56318,56254,56190,56126,56062,55998,55934,55870,
55806,55742,55678,55614,55550,55486,55422,55358,
55294,55230,55166,55102,55038,54974,54910,54846,
54782,54718,54654,54590,54526,54462,54398,54334,
54270,54206,54142,54078,54014,53950,53886,53822,
53758,53694,53630,53566,53502,53438,53374,53310,
53246,53182,53118,53054,52990,52926,52862,52798,
52734,52670,52606,52542,52478,52414,52350,52286,
52222,52158,52094,52030,51966,51902,51838,51774,
51710,51646,51582,51518,51454,51390,51326,51262,
51198,51134,51070,51006,50942,50878,50814,50750,
50686,50622,50558,50494,50430,50366,50302,50238,
50174,50110,50046,49982,49918,49854,49790,49726,
49662,49598,49534,49470,49406,49342,49278,49214,
49150,49087,49023,48959,48895,48831,48767,48703,
48639,48575,48511,48447,48383,48319,48255,48191,
48127,48063,47999,47935,47871,47807,47743,47679,
47615,47551,47487,47423,47359,47295,47231,47167,
47103,47039,46975,46911,46847,46783,46719,46655,
46591,46527,46463,46399,46335,46271,46207,46143,
46079,46015,45951,45887,45823,45759,45695,45631,
45567,45503,45439,45375,45311,45247,45183,45119,
45055,44991,44927,44863,44799,44735,44671,44607,
44543,44479,44415,44351,44287,44223,44159,44095,
44031,43967,43903,43839,43775,43711,43647,43583,
43519,43455,43391,43327,43263,43199,43135,43071,
43007,42943,42879,42815,42751,42687,42623,42559,
42495,42431,42367,42303,42239,42175,42111,42047,
41983,41919,41855,41791,41727,41663,41599,41535,
41471,41407,41343,41279,41215,41151,41087,41023,
40959,40895,40831,40767,40703,40639,40575,40511,
40447,40383,40319,40255,40191,40127,40063,39999,
39935,39871,39807,39743,39679,39615,39551,39487,
39423,39359,39295,39231,39167,39103,39039,38975,
38911,38847,38783,38719,38655,38591,38527,38463,
38399,38335,38271,38207,38143,38079,38015,37951,
37887,37823,37759,37695,37631,37567,37503,37439,
37375,37311,37247,37183,37119,37055,36991,36927,
36863,36799,36735,36671,36607,36543,36479,36415,
36351,36287,36223,36159,36095,36031,35967,35903,
35839,35775,35711,35647,35583,35519,35455,35391,
35327,35263,35199,35135,35071,35007,34943,34879,
34815,34751,34687,34623,34559,34495,34431,34367,
34303,34239,34175,34111,34047,33983,33919,33855,
33791,33727,33663,33599,33535,33471,33407,33343,
33279,33215,33151,33087,33023,32959,32895,32831,
32767,32703,32639,32575,32511,32447,32383,32319,
32255,32191,32127,32063,31999,31935,31871,31807,
31743,31679,31615,31551,31487,31423,31359,31295,
31231,31167,31103,31039,30975,30911,30847,30783,
30719,30655,30591,30527,30463,30399,30335,30271,
30207,30143,30079,30015,29951,29887,29823,29759,
29695,29631,29567,29503,29439,29375,29311,29247,
29183,29119,29055,28991,28927,28863,28799,28735,
28671,28607,28543,28479,28415,28351,28287,28223,
28159,28095,28031,27967,27903,27839,27775,27711,
27647,27583,27519,27455,27391,27327,27263,27199,
27135,27071,27007,26943,26879,26815,26751,26687,
26623,26559,26495,26431,26367,26303,26239,26175,
26111,26047,25983,25919,25855,25791,25727,25663,
25599,25535,25471,25407,25343,25279,25215,25151,
25087,25023,24959,24895,24831,24767,24703,24639,
24575,24511,24447,24383,24319,24255,24191,24127,
24063,23999,23935,23871,23807,23743,23679,23615,
23551,23487,23423,23359,23295,23231,23167,23103,
23039,22975,22911,22847,22783,22719,22655,22591,
22527,22463,22399,22335,22271,22207,22143,22079,
22015,21951,21887,21823,21759,21695,21631,21567,
21503,21439,21375,21311,21247,21183,21119,21055,
20991,20927,20863,20799,20735,20671,20607,20543,
20479,20415,20351,20287,20223,20159,20095,20031,
19967,19903,19839,19775,19711,19647,19583,19519,
19455,19391,19327,19263,19199,19135,19071,19007,
18943,18879,18815,18751,18687,18623,18559,18495,
18431,18367,18303,18239,18175,18111,18047,17983,
17919,17855,17791,17727,17663,17599,17535,17471,
17407,17343,17279,17215,17151,17087,17023,16959,
16895,16831,16767,16703,16639,16575,16511,16447,
16384,16320,16256,16192,16128,16064,16000,15936,
15872,15808,15744,15680,15616,15552,15488,15424,
15360,15296,15232,15168,15104,15040,14976,14912,
14848,14784,14720,14656,14592,14528,14464,14400,
14336,14272,14208,14144,14080,14016,13952,13888,
13824,13760,13696,13632,13568,13504,13440,13376,
13312,13248,13184,13120,13056,12992,12928,12864,
12800,12736,12672,12608,12544,12480,12416,12352,
12288,12224,12160,12096,12032,11968,11904,11840,
11776,11712,11648,11584,11520,11456,11392,11328,
11264,11200,11136,11072,11008,10944,10880,10816,
10752,10688,10624,10560,10496,10432,10368,10304,
10240,10176,10112,10048, 9984, 9920, 9856, 9792,
9728, 9664, 9600, 9536, 9472, 9408, 9344, 9280,
9216, 9152, 9088, 9024, 8960, 8896, 8832, 8768,
8704, 8640, 8576, 8512, 8448, 8384, 8320, 8256,
8192, 8128, 8064, 8000, 7936, 7872, 7808, 7744,
7680, 7616, 7552, 7488, 7424, 7360, 7296, 7232,
7168, 7104, 7040, 6976, 6912, 6848, 6784, 6720,
6656, 6592, 6528, 6464, 6400, 6336, 6272, 6208,
6144, 6080, 6016, 5952, 5888, 5824, 5760, 5696,
5632, 5568, 5504, 5440, 5376, 5312, 5248, 5184,
5120, 5056, 4992, 4928, 4864, 4800, 4736, 4672,
4608, 4544, 4480, 4416, 4352, 4288, 4224, 4160,
4096, 4032, 3968, 3904, 3840, 3776, 3712, 3648,
3584, 3520, 3456, 3392, 3328, 3264, 3200, 3136,
3072, 3008, 2944, 2880, 2816, 2752, 2688, 2624,
2560, 2496, 2432, 2368, 2304, 2240, 2176, 2112,
2048, 1984, 1920, 1856, 1792, 1728, 1664, 1600,
1536, 1472, 1408, 1344, 1280, 1216, 1152, 1088,
1024,  960,  896,  832,  768,  704,  640,  576,
 512,  448,  384,  320,  256,  192,  128,   64 };

/* USER CODE END PV */

void SystemClock_Config(void);
static void MX_GPIO_Init(void);
static void MX_ADC1_Init(void);
static void MX_HRTIM1_Init(void);
static void MX_DAC1_Init(void);
static void MX_DAC2_Init(void);
static void MX_TIM6_Init(void);
/* USER CODE BEGIN PFP */
void DAC_Start();
void DAC_Stop();
void DAC_Set();
void Gate_Toggle_L();
void Gate_Toggle_H();
void initialize_dds();
void Speed_LED();
void Channel_LED();
void EndPoint_Handle();
/* USER CODE END PFP */

/* USER CODE BEGIN 0 */
void HAL_GPIO_EXTI_Callback(uint16_t GPIO_Pin)
{
	switch (GPIO_Pin) {
		case Channel_Select_Pin:
			DAC_Stop();
			channel++;
			if(channel > 3)
				channel -= 3;
			Channel_LED();
			DAC_Start();
			break;
		case Speed_Pin:
			spd++;
			if(spd > 3)
				spd = 0;
//			initialize_dds();
			Speed_LED();
			break;
		case Forward_Pin:
			if(HAL_GPIO_ReadPin(Forward_GPIO_Port, Forward_Pin) == 1)
			{
				backwards = false;
				buttonRelease = false;
//				EndPoint_Handle();
				initialize_dds();
//				DAC_Start();
				buttonPress = true;
			}
			else if(HAL_GPIO_ReadPin(Forward_GPIO_Port, Forward_Pin) == 0)
				buttonRelease = true;
			break;
		case Backward_Pin:
			if(HAL_GPIO_ReadPin(Backward_GPIO_Port, Backward_Pin) == 1)
			{
				backwards = true;
				buttonRelease = false;
//				EndPoint_Handle();
				initialize_dds();
//				DAC_Start();
				buttonPress = true;
			}
			else if(HAL_GPIO_ReadPin(Backward_GPIO_Port, Backward_Pin) == 0)
				buttonRelease = true;
			break;
		default:
//			endPoint = true;
//			EndPoint_Handle();
			break;
	}
}

void HAL_TIM_PeriodElapsedCallback(TIM_HandleTypeDef *htim)
{
		if(htim == &htim6 && gateOn == false && ((buttonPress == true && stepNumber == 0) || ((stepCounter <= stepNumber) && stepNumber != 0)))
		{
//			DAC_Set();
			phaseAccumulator += phaseIncrement;
			if (phaseAccumulator >= periodLen)
			{
				phaseAccumulator = 0;
				if(pulse == true)
				{
					Gate_Toggle_L();
					gateOn = true;
				}
				else if(endPoint == true || (buttonRelease == true && stepNumber == 0) || ((stepCounter == stepNumber) && stepNumber != 0))
				{
//					DAC_Stop();
					HAL_DAC_SetValue(&hdac1, DAC_CHANNEL_1, DAC_ALIGN_12B_L, 0);
					buttonPress = false;
//					endPoint = false;
					stepCounter = 0;
					stepNumber = 0;

				}
				else
					stepCounter++;
			}
			DAC_Set();
		}
		else if(htim == &htim6 && gateOn == true)
		{
			pulseAccumulator ++;
			if(pulseAccumulator >= pulseLen-1 && backwards == true && bootCharging == true)
			{
				Gate_Toggle_L();
				Gate_Toggle_H();
			}
			else if(pulseAccumulator >= pulseLen)
			{
				pulseAccumulator = 0;
				if(backwards == true)
					Gate_Toggle_H();
				else
					Gate_Toggle_L();
				gateOn = false;
				stepCounter ++;
				if(endPoint == true || (buttonRelease == true && stepNumber == 0) || ((stepCounter == stepNumber) && stepNumber != 0))
				{
					buttonPress = false;
//					DAC_Stop();
					HAL_DAC_SetValue(&hdac1, DAC_CHANNEL_1, DAC_ALIGN_12B_L, 0);
//					endPoint = false;
					stepCounter = 0;
					stepNumber = 0;
				}
			}
		}
}

void DAC_Start()
{
	switch (channel) {
		case 1:
			HAL_DAC_Start(&hdac1, DAC_CHANNEL_1);
			break;
		case 2:
			HAL_DAC_Start(&hdac1, DAC_CHANNEL_2);
			break;
		case 3:
			HAL_DAC_Start(&hdac2, DAC_CHANNEL_1);
			break;
	}
}

void DAC_Stop()
{
	switch (channel) {
		case 1:
			HAL_DAC_Stop(&hdac1, DAC_CHANNEL_1);
			break;
		case 2:
			HAL_DAC_Stop(&hdac1, DAC_CHANNEL_2);
			break;
		case 3:
			HAL_DAC_Stop(&hdac2, DAC_CHANNEL_1);
			break;
	}
}

void DAC_Set()
{
	uint16_t dacValue = Lut[phaseAccumulator + phaseShift] * amplitude + offset;
	switch (channel) {
		case 1:
			HAL_DAC_SetValue(&hdac1, DAC_CHANNEL_1, DAC_ALIGN_12B_L, dacValue);
			break;
		case 2:
			HAL_DAC_SetValue(&hdac1, DAC_CHANNEL_2, DAC_ALIGN_12B_L, dacValue);
			break;
		case 3:
			HAL_DAC_SetValue(&hdac2, DAC_CHANNEL_1, DAC_ALIGN_12B_L, dacValue);
			break;
	}
}

void Gate_Toggle_L()
{
	switch (channel) {
		case 1:
			HAL_GPIO_TogglePin(Gate_LI1_GPIO_Port, Gate_LI1_Pin);
			break;
		case 2:
			HAL_GPIO_TogglePin(Gate_LI2_GPIO_Port, Gate_LI2_Pin);
			break;
		case 3:
			HAL_GPIO_TogglePin(Gate_LI3_GPIO_Port, Gate_LI3_Pin);
			break;
	}
	bootCharging = !bootCharging;
}

void Gate_Toggle_H()
{
	switch (channel) {
		case 1:
				HAL_GPIO_TogglePin(Gate_HI1_GPIO_Port, Gate_HI1_Pin);
			break;
		case 2:
				HAL_GPIO_TogglePin(Gate_HI2_GPIO_Port, Gate_HI2_Pin);
			break;
		case 3:
				HAL_GPIO_TogglePin(Gate_HI3_GPIO_Port, Gate_HI3_Pin);
			break;
	}
}

void Speed_LED()
{
	switch (spd) {
		case 0:
			HAL_GPIO_WritePin(LED_SPD1_GPIO_Port, LED_SPD1_Pin, GPIO_PIN_RESET);
			HAL_GPIO_WritePin(LED_SPD2_GPIO_Port, LED_SPD2_Pin, GPIO_PIN_RESET);
			HAL_GPIO_WritePin(LED_SPD3_GPIO_Port, LED_SPD3_Pin, GPIO_PIN_RESET);
			break;
		case 1:
			HAL_GPIO_WritePin(LED_SPD1_GPIO_Port, LED_SPD1_Pin, GPIO_PIN_SET);
			break;
		case 2:
			HAL_GPIO_WritePin(LED_SPD1_GPIO_Port, LED_SPD1_Pin, GPIO_PIN_SET);
			HAL_GPIO_WritePin(LED_SPD2_GPIO_Port, LED_SPD2_Pin, GPIO_PIN_SET);
			break;
		case 3:
			HAL_GPIO_WritePin(LED_SPD1_GPIO_Port, LED_SPD1_Pin, GPIO_PIN_SET);
			HAL_GPIO_WritePin(LED_SPD2_GPIO_Port, LED_SPD2_Pin, GPIO_PIN_SET);
			HAL_GPIO_WritePin(LED_SPD3_GPIO_Port, LED_SPD3_Pin, GPIO_PIN_SET);
			break;
	}
}
void Channel_LED()
{
	switch (channel) {
		case 1:
			HAL_GPIO_WritePin(LED_CH3_GPIO_Port, LED_CH3_Pin, GPIO_PIN_RESET);
			HAL_GPIO_WritePin(LED_CH1_GPIO_Port, LED_CH1_Pin, GPIO_PIN_SET);
			break;
		case 2:
			HAL_GPIO_WritePin(LED_CH1_GPIO_Port, LED_CH1_Pin, GPIO_PIN_RESET);
			HAL_GPIO_WritePin(LED_CH2_GPIO_Port, LED_CH2_Pin, GPIO_PIN_SET);
			break;
		case 3:
			HAL_GPIO_WritePin(LED_CH2_GPIO_Port, LED_CH2_Pin, GPIO_PIN_RESET);
			HAL_GPIO_WritePin(LED_CH3_GPIO_Port, LED_CH3_Pin, GPIO_PIN_SET);
			break;
	}
}

void EndPoint_Handle()
{

}

void initialize_dds()
{
	float ph;				//Phase shift [0-2*Pi]
	uint16_t freq;			//Frequency of the generated signal [Hz]
	float ampl;				//Peak to peak voltage of the generated signal [V]
	float off;				//Offset [V]
	float period;			//Fraction of the full period to be generated [0-1]
	float pls;				//Fraction of the generated signal to be the pulse duration [0-1]
//	uint16_t timeOn = 0;	//Time of the output signal generation [ms]. When set to 0, the signal is generated only while the button is kept pressed
//	float stepLen;

	pulse = false;	//Preset flag

	switch (spd) {
		case 0:
			ph = 0;
			if(backwards == true)
			{
				ph = Pi;
				stepNumber = 3200;
			}
			else
				stepNumber = 3295/1.6;
			freq = 1100;
			ampl = 2.9*.91;//3.17;//3.115;
			off = .08;//.125;
			period = .5;
			pls = .1;
			Lut = sawLut;
			break;
		case 1:
			ph = 0;
			if(backwards == true)
				ph = Pi;
			freq = 1250;
			ampl = 2.9*.91;
			off = .08;
			period = .5;
			pls = .1;
			Lut = sawLut;
//			timeOn = 500;
			break;
		case 2:
			ph = 3*Pi/2;
			if(backwards == true)
				ph = Pi/2;
			freq = 6600;
			ampl = 3.17*.826;
			off = .08;
			period = .5;
			pls = .1;
			Lut = sinLut;
			break;
		case 3:
			ph = 3*Pi/2;
			if(backwards == true)
				ph = Pi/2;
			freq = 1100;
			ampl = 3.235*2*.826;
			off = .0815;
			if(backwards == true)
				off += .636;
			period = .25;
			pls = .1;
			Lut = sinLut;
			break;
	}

	stepNumber = 0;
	if(pls > 0)
		pulse = true;
	periodLen = lutLen * period;
	phaseIncrement = (freq / 140625.0)*periodLen;
	amplitude = (ampl / 3.3);
	offset = (off * 65534)/3.3;
	phaseShift = (ph * lutLen)/(2 * Pi);
	pulseLen = (periodLen/phaseIncrement)*pls;
//	stepLen = 1000*((periodLen / phaseIncrement) + pulseLen)/140625.0;	//milliseconds
//	stepNumber = timeOn / stepLen;	//Number of steps needed to elapse set time. Can also be set manually here
	phaseAccumulator = 0;
}
/* USER CODE END 0 */

int main(void)
{

  /* MCU Configuration--------------------------------------------------------*/

  /* Reset of all peripherals, Initializes the Flash interface and the Systick. */
  HAL_Init();

  /* Configure the system clock */
  SystemClock_Config();

  /* Initialize all configured peripherals */
  MX_GPIO_Init();
  MX_ADC1_Init();
  MX_HRTIM1_Init();
  MX_DAC1_Init();
  MX_DAC2_Init();
  MX_TIM6_Init();
  /* USER CODE BEGIN 2 */
//  initialize_dds();
  Speed_LED();
  Channel_LED();
  HAL_TIM_Base_Start_IT(&htim6);
//  HAL_DAC_Start(&hdac1, DAC_CHANNEL_1);
  DAC_Start();

  /* USER CODE END 2 */

  /* Infinite loop */
  while (1)
  {

  }
}

void SystemClock_Config(void)
{
  RCC_OscInitTypeDef RCC_OscInitStruct = {0};
  RCC_ClkInitTypeDef RCC_ClkInitStruct = {0};
  RCC_PeriphCLKInitTypeDef PeriphClkInit = {0};

  /** Initializes the RCC Oscillators according to the specified parameters
  * in the RCC_OscInitTypeDef structure.
  */
  RCC_OscInitStruct.OscillatorType = RCC_OSCILLATORTYPE_HSE;
  RCC_OscInitStruct.HSEState = RCC_HSE_BYPASS;
  RCC_OscInitStruct.HSEPredivValue = RCC_HSE_PREDIV_DIV1;
  RCC_OscInitStruct.HSIState = RCC_HSI_ON;
  RCC_OscInitStruct.PLL.PLLState = RCC_PLL_ON;
  RCC_OscInitStruct.PLL.PLLSource = RCC_PLLSOURCE_HSE;
  RCC_OscInitStruct.PLL.PLLMUL = RCC_PLL_MUL9;
  if (HAL_RCC_OscConfig(&RCC_OscInitStruct) != HAL_OK)
  {
    Error_Handler();
  }

  /** Initializes the CPU, AHB and APB buses clocks
  */
  RCC_ClkInitStruct.ClockType = RCC_CLOCKTYPE_HCLK|RCC_CLOCKTYPE_SYSCLK
                              |RCC_CLOCKTYPE_PCLK1|RCC_CLOCKTYPE_PCLK2;
  RCC_ClkInitStruct.SYSCLKSource = RCC_SYSCLKSOURCE_PLLCLK;
  RCC_ClkInitStruct.AHBCLKDivider = RCC_SYSCLK_DIV1;
  RCC_ClkInitStruct.APB1CLKDivider = RCC_HCLK_DIV2;
  RCC_ClkInitStruct.APB2CLKDivider = RCC_HCLK_DIV1;

  if (HAL_RCC_ClockConfig(&RCC_ClkInitStruct, FLASH_LATENCY_2) != HAL_OK)
  {
    Error_Handler();
  }
  PeriphClkInit.PeriphClockSelection = RCC_PERIPHCLK_HRTIM1|RCC_PERIPHCLK_ADC12;
  PeriphClkInit.Adc12ClockSelection = RCC_ADC12PLLCLK_DIV1;
  PeriphClkInit.Hrtim1ClockSelection = RCC_HRTIM1CLK_HCLK;
  if (HAL_RCCEx_PeriphCLKConfig(&PeriphClkInit) != HAL_OK)
  {
    Error_Handler();
  }
}

static void MX_ADC1_Init(void)
{

  ADC_MultiModeTypeDef multimode = {0};
  ADC_ChannelConfTypeDef sConfig = {0};

  /** Common config
  */
  hadc1.Instance = ADC1;
  hadc1.Init.ClockPrescaler = ADC_CLOCK_ASYNC_DIV1;
  hadc1.Init.Resolution = ADC_RESOLUTION_12B;
  hadc1.Init.ScanConvMode = ADC_SCAN_DISABLE;
  hadc1.Init.ContinuousConvMode = DISABLE;
  hadc1.Init.DiscontinuousConvMode = DISABLE;
  hadc1.Init.ExternalTrigConvEdge = ADC_EXTERNALTRIGCONVEDGE_NONE;
  hadc1.Init.ExternalTrigConv = ADC_SOFTWARE_START;
  hadc1.Init.DataAlign = ADC_DATAALIGN_RIGHT;
  hadc1.Init.NbrOfConversion = 1;
  hadc1.Init.DMAContinuousRequests = DISABLE;
  hadc1.Init.EOCSelection = ADC_EOC_SINGLE_CONV;
  hadc1.Init.LowPowerAutoWait = DISABLE;
  hadc1.Init.Overrun = ADC_OVR_DATA_OVERWRITTEN;
  if (HAL_ADC_Init(&hadc1) != HAL_OK)
  {
    Error_Handler();
  }

  /** Configure the ADC multi-mode
  */
  multimode.Mode = ADC_MODE_INDEPENDENT;
  if (HAL_ADCEx_MultiModeConfigChannel(&hadc1, &multimode) != HAL_OK)
  {
    Error_Handler();
  }

  /** Configure Regular Channel
  */
  sConfig.Channel = ADC_CHANNEL_11;
  sConfig.Rank = ADC_REGULAR_RANK_1;
  sConfig.SingleDiff = ADC_SINGLE_ENDED;
  sConfig.SamplingTime = ADC_SAMPLETIME_1CYCLE_5;
  sConfig.OffsetNumber = ADC_OFFSET_NONE;
  sConfig.Offset = 0;
  if (HAL_ADC_ConfigChannel(&hadc1, &sConfig) != HAL_OK)
  {
    Error_Handler();
  }

}

static void MX_DAC1_Init(void)
{

  DAC_ChannelConfTypeDef sConfig = {0};

  /** DAC Initialization
  */
  hdac1.Instance = DAC1;
  if (HAL_DAC_Init(&hdac1) != HAL_OK)
  {
    Error_Handler();
  }

  /** DAC channel OUT1 config
  */
  sConfig.DAC_Trigger = DAC_TRIGGER_T6_TRGO;
  sConfig.DAC_OutputBuffer = DAC_OUTPUTBUFFER_ENABLE;
  if (HAL_DAC_ConfigChannel(&hdac1, &sConfig, DAC_CHANNEL_1) != HAL_OK)
  {
    Error_Handler();
  }

  /** DAC channel OUT2 config
  */
  sConfig.DAC_OutputSwitch = DAC_OUTPUTSWITCH_ENABLE;
  if (HAL_DAC_ConfigChannel(&hdac1, &sConfig, DAC_CHANNEL_2) != HAL_OK)
  {
    Error_Handler();
  }

}

static void MX_DAC2_Init(void)
{

  DAC_ChannelConfTypeDef sConfig = {0};

  /** DAC Initialization
  */
  hdac2.Instance = DAC2;
  if (HAL_DAC_Init(&hdac2) != HAL_OK)
  {
    Error_Handler();
  }

  /** DAC channel OUT1 config
  */
  sConfig.DAC_Trigger = DAC_TRIGGER_T6_TRGO;
  sConfig.DAC_OutputSwitch = DAC_OUTPUTSWITCH_ENABLE;
  if (HAL_DAC_ConfigChannel(&hdac2, &sConfig, DAC_CHANNEL_1) != HAL_OK)
  {
    Error_Handler();
  }

}

static void MX_HRTIM1_Init(void)
{

  HRTIM_TimeBaseCfgTypeDef pTimeBaseCfg = {0};
  HRTIM_TimerCfgTypeDef pTimerCfg = {0};
  HRTIM_OutputCfgTypeDef pOutputCfg = {0};

  hhrtim1.Instance = HRTIM1;
  hhrtim1.Init.HRTIMInterruptResquests = HRTIM_IT_NONE;
  hhrtim1.Init.SyncOptions = HRTIM_SYNCOPTION_NONE;
  if (HAL_HRTIM_Init(&hhrtim1) != HAL_OK)
  {
    Error_Handler();
  }
  pTimeBaseCfg.Period = 0xFFFD;
  pTimeBaseCfg.RepetitionCounter = 0x00;
  pTimeBaseCfg.PrescalerRatio = HRTIM_PRESCALERRATIO_DIV1;
  pTimeBaseCfg.Mode = HRTIM_MODE_CONTINUOUS;
  if (HAL_HRTIM_TimeBaseConfig(&hhrtim1, HRTIM_TIMERINDEX_TIMER_C, &pTimeBaseCfg) != HAL_OK)
  {
    Error_Handler();
  }
  pTimerCfg.InterruptRequests = HRTIM_TIM_IT_NONE;
  pTimerCfg.DMARequests = HRTIM_TIM_DMA_NONE;
  pTimerCfg.DMASrcAddress = 0x0000;
  pTimerCfg.DMADstAddress = 0x0000;
  pTimerCfg.DMASize = 0x1;
  pTimerCfg.HalfModeEnable = HRTIM_HALFMODE_DISABLED;
  pTimerCfg.StartOnSync = HRTIM_SYNCSTART_DISABLED;
  pTimerCfg.ResetOnSync = HRTIM_SYNCRESET_DISABLED;
  pTimerCfg.DACSynchro = HRTIM_DACSYNC_NONE;
  pTimerCfg.PreloadEnable = HRTIM_PRELOAD_DISABLED;
  pTimerCfg.UpdateGating = HRTIM_UPDATEGATING_INDEPENDENT;
  pTimerCfg.BurstMode = HRTIM_TIMERBURSTMODE_MAINTAINCLOCK;
  pTimerCfg.RepetitionUpdate = HRTIM_UPDATEONREPETITION_DISABLED;
  pTimerCfg.PushPull = HRTIM_TIMPUSHPULLMODE_DISABLED;
  pTimerCfg.FaultEnable = HRTIM_TIMFAULTENABLE_NONE;
  pTimerCfg.FaultLock = HRTIM_TIMFAULTLOCK_READWRITE;
  pTimerCfg.DeadTimeInsertion = HRTIM_TIMDEADTIMEINSERTION_DISABLED;
  pTimerCfg.DelayedProtectionMode = HRTIM_TIMER_A_B_C_DELAYEDPROTECTION_DISABLED;
  pTimerCfg.UpdateTrigger = HRTIM_TIMUPDATETRIGGER_NONE;
  pTimerCfg.ResetTrigger = HRTIM_TIMRESETTRIGGER_NONE;
  pTimerCfg.ResetUpdate = HRTIM_TIMUPDATEONRESET_DISABLED;
  if (HAL_HRTIM_WaveformTimerConfig(&hhrtim1, HRTIM_TIMERINDEX_TIMER_C, &pTimerCfg) != HAL_OK)
  {
    Error_Handler();
  }
  pOutputCfg.Polarity = HRTIM_OUTPUTPOLARITY_HIGH;
  pOutputCfg.SetSource = HRTIM_OUTPUTSET_NONE;
  pOutputCfg.ResetSource = HRTIM_OUTPUTRESET_NONE;
  pOutputCfg.IdleMode = HRTIM_OUTPUTIDLEMODE_NONE;
  pOutputCfg.IdleLevel = HRTIM_OUTPUTIDLELEVEL_INACTIVE;
  pOutputCfg.FaultLevel = HRTIM_OUTPUTFAULTLEVEL_NONE;
  pOutputCfg.ChopperModeEnable = HRTIM_OUTPUTCHOPPERMODE_DISABLED;
  pOutputCfg.BurstModeEntryDelayed = HRTIM_OUTPUTBURSTMODEENTRY_REGULAR;
  if (HAL_HRTIM_WaveformOutputConfig(&hhrtim1, HRTIM_TIMERINDEX_TIMER_C, HRTIM_OUTPUT_TC1, &pOutputCfg) != HAL_OK)
  {
    Error_Handler();
  }
  HAL_HRTIM_MspPostInit(&hhrtim1);

}

static void MX_TIM6_Init(void)
{

  TIM_MasterConfigTypeDef sMasterConfig = {0};

  htim6.Instance = TIM6;
  htim6.Init.Prescaler = 32-1;
  htim6.Init.CounterMode = TIM_COUNTERMODE_UP;
  htim6.Init.Period = 16-1;
  htim6.Init.AutoReloadPreload = TIM_AUTORELOAD_PRELOAD_DISABLE;
  if (HAL_TIM_Base_Init(&htim6) != HAL_OK)
  {
    Error_Handler();
  }
  sMasterConfig.MasterOutputTrigger = TIM_TRGO_UPDATE;
  sMasterConfig.MasterSlaveMode = TIM_MASTERSLAVEMODE_DISABLE;
  if (HAL_TIMEx_MasterConfigSynchronization(&htim6, &sMasterConfig) != HAL_OK)
  {
    Error_Handler();
  }

}

static void MX_GPIO_Init(void)
{
  GPIO_InitTypeDef GPIO_InitStruct = {0};

  /* GPIO Ports Clock Enable */
  __HAL_RCC_GPIOC_CLK_ENABLE();
  __HAL_RCC_GPIOF_CLK_ENABLE();
  __HAL_RCC_GPIOA_CLK_ENABLE();
  __HAL_RCC_GPIOB_CLK_ENABLE();

  /*Configure GPIO pin Output Level */
  HAL_GPIO_WritePin(GPIOC, Gate_HI1_Pin|Gate_LI1_Pin|Gate_HI2_Pin, GPIO_PIN_RESET);

  /*Configure GPIO pin Output Level */
  HAL_GPIO_WritePin(GPIOA, Gate_LI2_Pin|Gate_HI3_Pin, GPIO_PIN_RESET);

  /*Configure GPIO pin Output Level */
  HAL_GPIO_WritePin(GPIOB, Gate_LI3_Pin|LED_SPD1_Pin|LED_SPD3_Pin|LED_SPD2_Pin
                          |LED_CH3_Pin|LED_CH2_Pin|LED_CH1_Pin, GPIO_PIN_RESET);

  /*Configure GPIO pins : Gate_HI1_Pin Gate_LI1_Pin Gate_HI2_Pin */
  GPIO_InitStruct.Pin = Gate_HI1_Pin|Gate_LI1_Pin|Gate_HI2_Pin;
  GPIO_InitStruct.Mode = GPIO_MODE_OUTPUT_PP;
  GPIO_InitStruct.Pull = GPIO_NOPULL;
  GPIO_InitStruct.Speed = GPIO_SPEED_FREQ_LOW;
  HAL_GPIO_Init(GPIOC, &GPIO_InitStruct);

  /*Configure GPIO pins : Forward_Pin Backward_Pin */
  GPIO_InitStruct.Pin = Forward_Pin|Backward_Pin;
  GPIO_InitStruct.Mode = GPIO_MODE_IT_RISING_FALLING;
  GPIO_InitStruct.Pull = GPIO_NOPULL;
  HAL_GPIO_Init(GPIOA, &GPIO_InitStruct);

  /*Configure GPIO pins : Gate_LI2_Pin Gate_HI3_Pin */
  GPIO_InitStruct.Pin = Gate_LI2_Pin|Gate_HI3_Pin;
  GPIO_InitStruct.Mode = GPIO_MODE_OUTPUT_PP;
  GPIO_InitStruct.Pull = GPIO_NOPULL;
  GPIO_InitStruct.Speed = GPIO_SPEED_FREQ_LOW;
  HAL_GPIO_Init(GPIOA, &GPIO_InitStruct);

  /*Configure GPIO pins : Speed_Pin Channel_Select_Pin EndPoint3_2_Pin */
  GPIO_InitStruct.Pin = Speed_Pin|Channel_Select_Pin|EndPoint3_2_Pin;
  GPIO_InitStruct.Mode = GPIO_MODE_IT_RISING;
  GPIO_InitStruct.Pull = GPIO_NOPULL;
  HAL_GPIO_Init(GPIOA, &GPIO_InitStruct);

  /*Configure GPIO pins : Gate_LI3_Pin LED_SPD1_Pin LED_SPD3_Pin LED_SPD2_Pin
                           LED_CH3_Pin LED_CH2_Pin LED_CH1_Pin */
  GPIO_InitStruct.Pin = Gate_LI3_Pin|LED_SPD1_Pin|LED_SPD3_Pin|LED_SPD2_Pin
                          |LED_CH3_Pin|LED_CH2_Pin|LED_CH1_Pin;
  GPIO_InitStruct.Mode = GPIO_MODE_OUTPUT_PP;
  GPIO_InitStruct.Pull = GPIO_NOPULL;
  GPIO_InitStruct.Speed = GPIO_SPEED_FREQ_LOW;
  HAL_GPIO_Init(GPIOB, &GPIO_InitStruct);

  /*Configure GPIO pins : EndPoint3_1_Pin EndPoint2_2_Pin EndPoint2_1_Pin EndPoint1_2_Pin
                           EndPoint1_1_Pin */
  GPIO_InitStruct.Pin = EndPoint3_1_Pin|EndPoint2_2_Pin|EndPoint2_1_Pin|EndPoint1_2_Pin
                          |EndPoint1_1_Pin;
  GPIO_InitStruct.Mode = GPIO_MODE_IT_RISING;
  GPIO_InitStruct.Pull = GPIO_NOPULL;
  HAL_GPIO_Init(GPIOB, &GPIO_InitStruct);

  /* EXTI interrupt init*/
  HAL_NVIC_SetPriority(EXTI0_IRQn, 0, 0);
  HAL_NVIC_EnableIRQ(EXTI0_IRQn);

  HAL_NVIC_SetPriority(EXTI1_IRQn, 0, 0);
  HAL_NVIC_EnableIRQ(EXTI1_IRQn);

  HAL_NVIC_SetPriority(EXTI3_IRQn, 0, 0);
  HAL_NVIC_EnableIRQ(EXTI3_IRQn);

  HAL_NVIC_SetPriority(EXTI9_5_IRQn, 0, 0);
  HAL_NVIC_EnableIRQ(EXTI9_5_IRQn);

  HAL_NVIC_SetPriority(EXTI15_10_IRQn, 0, 0);
  HAL_NVIC_EnableIRQ(EXTI15_10_IRQn);

}

void Error_Handler(void)
{
  __disable_irq();
  while (1)
  {
  }
}
